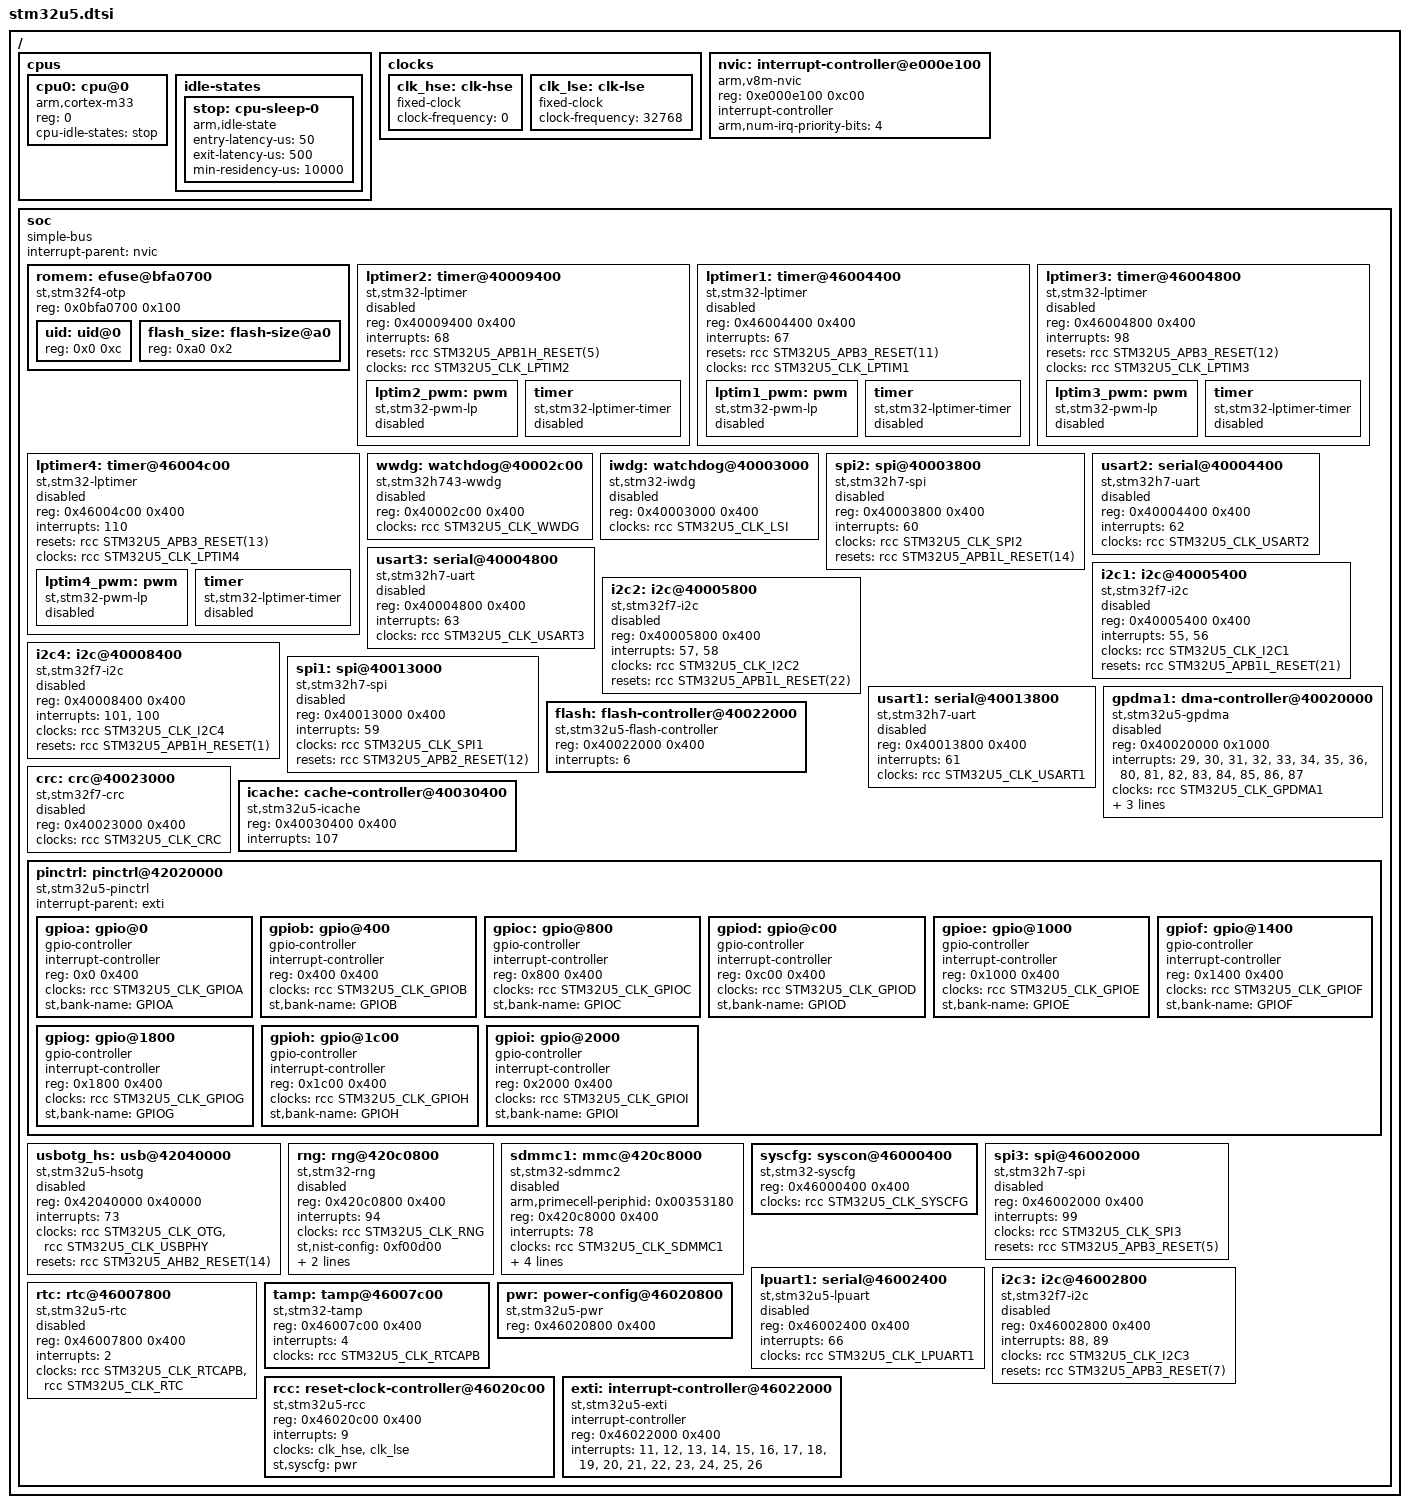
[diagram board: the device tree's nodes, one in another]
// SPDX-FileCopyrightText: 2026 Core Devices LLC
// SPDX-License-Identifier: (GPL-2.0-only OR BSD-2-Clause)

// The STM32U5 series, its non-secure aliases: TrustZone stays off

#include <dt-bindings/clock/st,stm32u5-rcc.h>
#include <dt-bindings/interrupt-controller/irq.h>
#include <dt-bindings/pinctrl/stm32-pinfunc.h>
#include <dt-bindings/reset/st,stm32u5-rcc.h>

/ {
	#address-cells = <1>;
	#size-cells = <1>;

	cpus {
		#address-cells = <1>;
		#size-cells = <0>;

		cpu0: cpu@0 {
			compatible = "arm,cortex-m33";
			device_type = "cpu";
			reg = <0>;
			cpu-idle-states = <&stop>;
		};

		idle-states {
			// Stop 2, the time back mostly MSIS and PLL1 starting again
			stop: cpu-sleep-0 {
				compatible = "arm,idle-state";
				entry-latency-us = <50>;
				exit-latency-us = <500>;
				min-residency-us = <10000>;
			};
		};
	};

	clocks {
		clk_hse: clk-hse {
			compatible = "fixed-clock";
			#clock-cells = <0>;
			clock-frequency = <0>;
		};

		clk_lse: clk-lse {
			compatible = "fixed-clock";
			#clock-cells = <0>;
			clock-frequency = <32768>;
		};
	};

	nvic: interrupt-controller@e000e100 {
		compatible = "arm,v8m-nvic";
		reg = <0xe000e100 0xc00>;
		interrupt-controller;
		#interrupt-cells = <1>;
		#address-cells = <0>;
		arm,num-irq-priority-bits = <4>;
	};

	soc {
		compatible = "simple-bus";
		#address-cells = <1>;
		#size-cells = <1>;
		interrupt-parent = <&nvic>;
		ranges;

		// The unique ID and the flash size, in system memory
		romem: efuse@bfa0700 {
			compatible = "st,stm32f4-otp";
			reg = <0x0bfa0700 0x100>;
			#address-cells = <1>;
			#size-cells = <1>;

			uid: uid@0 {
				reg = <0x0 0xc>;
			};

			flash_size: flash-size@a0 {
				reg = <0xa0 0x2>;
			};
		};

		lptimer2: timer@40009400 {
			compatible = "st,stm32-lptimer";
			reg = <0x40009400 0x400>;
			interrupts = <68>;
			resets = <&rcc STM32U5_APB1H_RESET(5)>;
			clocks = <&rcc STM32U5_CLK_LPTIM2>;
			clock-names = "mux";
			status = "disabled";

			lptim2_pwm: pwm {
				compatible = "st,stm32-pwm-lp";
				#pwm-cells = <3>;
				status = "disabled";
			};

			timer {
				compatible = "st,stm32-lptimer-timer";
				status = "disabled";
			};
		};

		lptimer1: timer@46004400 {
			compatible = "st,stm32-lptimer";
			reg = <0x46004400 0x400>;
			interrupts = <67>;
			resets = <&rcc STM32U5_APB3_RESET(11)>;
			clocks = <&rcc STM32U5_CLK_LPTIM1>;
			clock-names = "mux";
			status = "disabled";

			lptim1_pwm: pwm {
				compatible = "st,stm32-pwm-lp";
				#pwm-cells = <3>;
				status = "disabled";
			};

			timer {
				compatible = "st,stm32-lptimer-timer";
				status = "disabled";
			};
		};

		lptimer3: timer@46004800 {
			compatible = "st,stm32-lptimer";
			reg = <0x46004800 0x400>;
			interrupts = <98>;
			resets = <&rcc STM32U5_APB3_RESET(12)>;
			clocks = <&rcc STM32U5_CLK_LPTIM3>;
			clock-names = "mux";
			status = "disabled";

			lptim3_pwm: pwm {
				compatible = "st,stm32-pwm-lp";
				#pwm-cells = <3>;
				status = "disabled";
			};

			timer {
				compatible = "st,stm32-lptimer-timer";
				status = "disabled";
			};
		};

		// LPTIM4 shares its kernel clock selection with LPTIM3
		lptimer4: timer@46004c00 {
			compatible = "st,stm32-lptimer";
			reg = <0x46004c00 0x400>;
			interrupts = <110>;
			resets = <&rcc STM32U5_APB3_RESET(13)>;
			clocks = <&rcc STM32U5_CLK_LPTIM4>;
			clock-names = "mux";
			status = "disabled";

			lptim4_pwm: pwm {
				compatible = "st,stm32-pwm-lp";
				#pwm-cells = <3>;
				status = "disabled";
			};

			timer {
				compatible = "st,stm32-lptimer-timer";
				status = "disabled";
			};
		};

		wwdg: watchdog@40002c00 {
			compatible = "st,stm32h743-wwdg";
			reg = <0x40002c00 0x400>;
			clocks = <&rcc STM32U5_CLK_WWDG>;
			status = "disabled";
		};

		iwdg: watchdog@40003000 {
			compatible = "st,stm32-iwdg";
			reg = <0x40003000 0x400>;
			clocks = <&rcc STM32U5_CLK_LSI>;
			clock-names = "lsi";
			status = "disabled";
		};

		spi2: spi@40003800 {
			compatible = "st,stm32h7-spi";
			reg = <0x40003800 0x400>;
			interrupts = <60>;
			clocks = <&rcc STM32U5_CLK_SPI2>;
			resets = <&rcc STM32U5_APB1L_RESET(14)>;
			#address-cells = <1>;
			#size-cells = <0>;
			status = "disabled";
		};

		usart2: serial@40004400 {
			compatible = "st,stm32h7-uart";
			reg = <0x40004400 0x400>;
			interrupts = <62>;
			clocks = <&rcc STM32U5_CLK_USART2>;
			status = "disabled";
		};

		usart3: serial@40004800 {
			compatible = "st,stm32h7-uart";
			reg = <0x40004800 0x400>;
			interrupts = <63>;
			clocks = <&rcc STM32U5_CLK_USART3>;
			status = "disabled";
		};

		i2c1: i2c@40005400 {
			compatible = "st,stm32f7-i2c";
			reg = <0x40005400 0x400>;
			interrupts = <55>, <56>;
			interrupt-names = "event", "error";
			clocks = <&rcc STM32U5_CLK_I2C1>;
			resets = <&rcc STM32U5_APB1L_RESET(21)>;
			#address-cells = <1>;
			#size-cells = <0>;
			status = "disabled";
		};

		i2c2: i2c@40005800 {
			compatible = "st,stm32f7-i2c";
			reg = <0x40005800 0x400>;
			interrupts = <57>, <58>;
			interrupt-names = "event", "error";
			clocks = <&rcc STM32U5_CLK_I2C2>;
			resets = <&rcc STM32U5_APB1L_RESET(22)>;
			#address-cells = <1>;
			#size-cells = <0>;
			status = "disabled";
		};

		i2c4: i2c@40008400 {
			compatible = "st,stm32f7-i2c";
			reg = <0x40008400 0x400>;
			interrupts = <101>, <100>;
			interrupt-names = "event", "error";
			clocks = <&rcc STM32U5_CLK_I2C4>;
			resets = <&rcc STM32U5_APB1H_RESET(1)>;
			#address-cells = <1>;
			#size-cells = <0>;
			status = "disabled";
		};

		spi1: spi@40013000 {
			compatible = "st,stm32h7-spi";
			reg = <0x40013000 0x400>;
			interrupts = <59>;
			clocks = <&rcc STM32U5_CLK_SPI1>;
			resets = <&rcc STM32U5_APB2_RESET(12)>;
			#address-cells = <1>;
			#size-cells = <0>;
			status = "disabled";
		};

		usart1: serial@40013800 {
			compatible = "st,stm32h7-uart";
			reg = <0x40013800 0x400>;
			interrupts = <61>;
			clocks = <&rcc STM32U5_CLK_USART1>;
			status = "disabled";
		};

		// GPDMA1: 16 channels, 0 to 7 and 8 to 15 on two runs of interrupts
		gpdma1: dma-controller@40020000 {
			compatible = "st,stm32u5-gpdma";
			reg = <0x40020000 0x1000>;
			interrupts = <29>, <30>, <31>, <32>, <33>, <34>, <35>, <36>,
				     <80>, <81>, <82>, <83>, <84>, <85>, <86>, <87>;
			clocks = <&rcc STM32U5_CLK_GPDMA1>;
			resets = <&rcc STM32U5_AHB1_RESET(0)>;
			#dma-cells = <3>;
			dma-channels = <16>;
			dma-requests = <114>;
			status = "disabled";
		};

		flash: flash-controller@40022000 {
			compatible = "st,stm32u5-flash-controller";
			reg = <0x40022000 0x400>;
			interrupts = <6>;
			#address-cells = <1>;
			#size-cells = <1>;
		};

		crc: crc@40023000 {
			compatible = "st,stm32f7-crc";
			reg = <0x40023000 0x400>;
			clocks = <&rcc STM32U5_CLK_CRC>;
			status = "disabled";
		};

		// The instruction cache in front of the code bus, which the SoC turns on at boot
		icache: cache-controller@40030400 {
			compatible = "st,stm32u5-icache";
			reg = <0x40030400 0x400>;
			interrupts = <107>;
		};

		pinctrl: pinctrl@42020000 {
			compatible = "st,stm32u5-pinctrl";
			#address-cells = <1>;
			#size-cells = <1>;
			ranges = <0 0x42020000 0x2400>;
			interrupt-parent = <&exti>;

			gpioa: gpio@0 {
				gpio-controller;
				#gpio-cells = <2>;
				interrupt-controller;
				#interrupt-cells = <2>;
				reg = <0x0 0x400>;
				clocks = <&rcc STM32U5_CLK_GPIOA>;
				st,bank-name = "GPIOA";
			};

			gpiob: gpio@400 {
				gpio-controller;
				#gpio-cells = <2>;
				interrupt-controller;
				#interrupt-cells = <2>;
				reg = <0x400 0x400>;
				clocks = <&rcc STM32U5_CLK_GPIOB>;
				st,bank-name = "GPIOB";
			};

			gpioc: gpio@800 {
				gpio-controller;
				#gpio-cells = <2>;
				interrupt-controller;
				#interrupt-cells = <2>;
				reg = <0x800 0x400>;
				clocks = <&rcc STM32U5_CLK_GPIOC>;
				st,bank-name = "GPIOC";
			};

			gpiod: gpio@c00 {
				gpio-controller;
				#gpio-cells = <2>;
				interrupt-controller;
				#interrupt-cells = <2>;
				reg = <0xc00 0x400>;
				clocks = <&rcc STM32U5_CLK_GPIOD>;
				st,bank-name = "GPIOD";
			};

			gpioe: gpio@1000 {
				gpio-controller;
				#gpio-cells = <2>;
				interrupt-controller;
				#interrupt-cells = <2>;
				reg = <0x1000 0x400>;
				clocks = <&rcc STM32U5_CLK_GPIOE>;
				st,bank-name = "GPIOE";
			};

			gpiof: gpio@1400 {
				gpio-controller;
				#gpio-cells = <2>;
				interrupt-controller;
				#interrupt-cells = <2>;
				reg = <0x1400 0x400>;
				clocks = <&rcc STM32U5_CLK_GPIOF>;
				st,bank-name = "GPIOF";
			};

			// Supplied by VDDIO2, which the SoC declares valid at boot
			gpiog: gpio@1800 {
				gpio-controller;
				#gpio-cells = <2>;
				interrupt-controller;
				#interrupt-cells = <2>;
				reg = <0x1800 0x400>;
				clocks = <&rcc STM32U5_CLK_GPIOG>;
				st,bank-name = "GPIOG";
			};

			gpioh: gpio@1c00 {
				gpio-controller;
				#gpio-cells = <2>;
				interrupt-controller;
				#interrupt-cells = <2>;
				reg = <0x1c00 0x400>;
				clocks = <&rcc STM32U5_CLK_GPIOH>;
				st,bank-name = "GPIOH";
			};

			gpioi: gpio@2000 {
				gpio-controller;
				#gpio-cells = <2>;
				interrupt-controller;
				#interrupt-cells = <2>;
				reg = <0x2000 0x400>;
				clocks = <&rcc STM32U5_CLK_GPIOI>;
				st,bank-name = "GPIOI";
			};
		};

		usbotg_hs: usb@42040000 {
			compatible = "st,stm32u5-hsotg", "snps,dwc2";
			reg = <0x42040000 0x40000>;
			interrupts = <73>;
			clocks = <&rcc STM32U5_CLK_OTG>, <&rcc STM32U5_CLK_USBPHY>;
			clock-names = "otg", "utmi";
			resets = <&rcc STM32U5_AHB2_RESET(14)>;
			status = "disabled";
		};

		rng: rng@420c0800 {
			compatible = "st,stm32-rng";
			reg = <0x420c0800 0x400>;
			interrupts = <94>;
			clocks = <&rcc STM32U5_CLK_RNG>;
			// The NIST compliant configuration and health test, which the RNG takes when
			// conditioning is reset
			st,nist-config = <0xf00d00>;
			st,health-test-magic = <0x17590abc>;
			st,health-test-config = <0xaa74>;
			status = "disabled";
		};

		sdmmc1: mmc@420c8000 {
			compatible = "st,stm32-sdmmc2", "arm,pl18x", "arm,primecell";
			arm,primecell-periphid = <0x00353180>;
			reg = <0x420c8000 0x400>;
			interrupts = <78>;
			clocks = <&rcc STM32U5_CLK_SDMMC1>;
			clock-names = "apb_pclk";
			resets = <&rcc STM32U5_AHB2_RESET(27)>;
			cap-sd-highspeed;
			cap-mmc-highspeed;
			max-frequency = <80000000>;
			status = "disabled";
		};

		syscfg: syscon@46000400 {
			compatible = "st,stm32-syscfg", "syscon";
			reg = <0x46000400 0x400>;
			clocks = <&rcc STM32U5_CLK_SYSCFG>;
		};

		spi3: spi@46002000 {
			compatible = "st,stm32h7-spi";
			reg = <0x46002000 0x400>;
			interrupts = <99>;
			clocks = <&rcc STM32U5_CLK_SPI3>;
			resets = <&rcc STM32U5_APB3_RESET(5)>;
			#address-cells = <1>;
			#size-cells = <0>;
			status = "disabled";
		};

		// Its baud rate generator differs from that of the USARTs
		lpuart1: serial@46002400 {
			compatible = "st,stm32u5-lpuart";
			reg = <0x46002400 0x400>;
			interrupts = <66>;
			clocks = <&rcc STM32U5_CLK_LPUART1>;
			status = "disabled";
		};

		i2c3: i2c@46002800 {
			compatible = "st,stm32f7-i2c";
			reg = <0x46002800 0x400>;
			interrupts = <88>, <89>;
			interrupt-names = "event", "error";
			clocks = <&rcc STM32U5_CLK_I2C3>;
			resets = <&rcc STM32U5_APB3_RESET(7)>;
			#address-cells = <1>;
			#size-cells = <0>;
			status = "disabled";
		};

		rtc: rtc@46007800 {
			compatible = "st,stm32u5-rtc";
			reg = <0x46007800 0x400>;
			interrupts = <2>;
			clocks = <&rcc STM32U5_CLK_RTCAPB>, <&rcc STM32U5_CLK_RTC>;
			clock-names = "pclk", "rtc_ck";
			status = "disabled";
		};

		// The tamper block, with the backup registers
		tamp: tamp@46007c00 {
			compatible = "st,stm32-tamp", "syscon";
			reg = <0x46007c00 0x400>;
			interrupts = <4>;
			clocks = <&rcc STM32U5_CLK_RTCAPB>;
		};

		pwr: power-config@46020800 {
			compatible = "st,stm32u5-pwr";
			reg = <0x46020800 0x400>;
		};

		rcc: reset-clock-controller@46020c00 {
			compatible = "st,stm32u5-rcc";
			reg = <0x46020c00 0x400>;
			interrupts = <9>;
			#clock-cells = <1>;
			#reset-cells = <1>;
			clocks = <&clk_hse>, <&clk_lse>;
			clock-names = "hse", "lse";
			st,syscfg = <&pwr>;
		};

		exti: interrupt-controller@46022000 {
			compatible = "st,stm32u5-exti";
			interrupt-controller;
			#interrupt-cells = <2>;
			reg = <0x46022000 0x400>;
			interrupts = <11>, <12>, <13>, <14>, <15>, <16>, <17>, <18>,
				     <19>, <20>, <21>, <22>, <23>, <24>, <25>, <26>;
		};
	};
};
